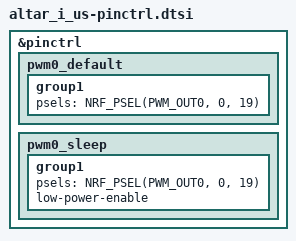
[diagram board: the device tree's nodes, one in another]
/*
* Copyright (c) 2023 The ZMK Contributors
* SPDX-License-Identifier: MIT
*/

&pinctrl {
    pwm0_default: pwm0_default {
        group1 {
            psels = <NRF_PSEL(PWM_OUT0, 0, 19)>;
        };
    };
    pwm0_sleep: pwm0_sleep {
        group1 {
            psels = <NRF_PSEL(PWM_OUT0, 0, 19)>;
            low-power-enable;
        };
    };
};
